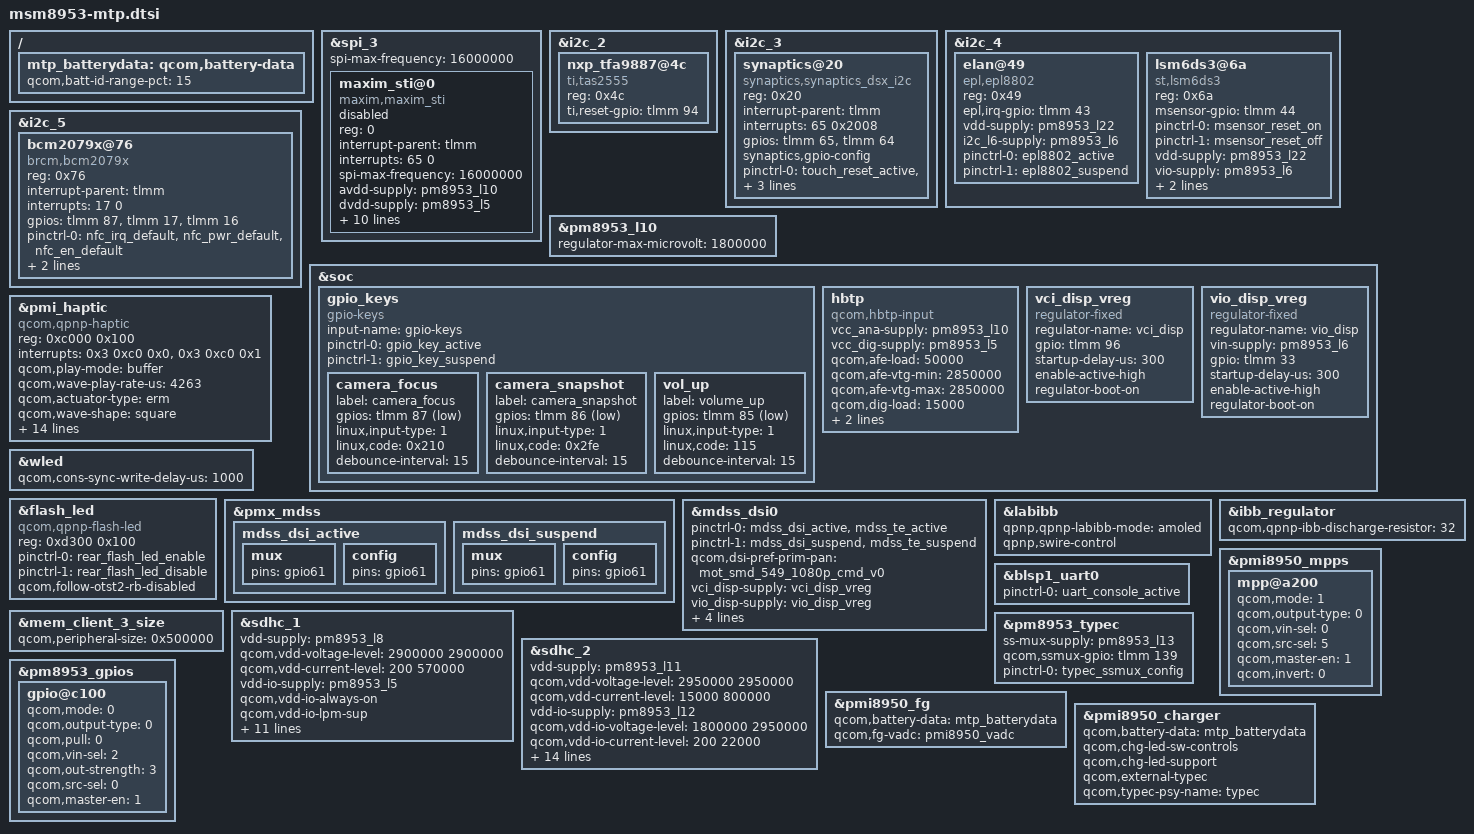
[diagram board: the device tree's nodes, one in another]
/*
 * Copyright (c) 2015-2016, The Linux Foundation. All rights reserved.
 *
 * This program is free software; you can redistribute it and/or modify
 * it under the terms of the GNU General Public License version 2 and
 * only version 2 as published by the Free Software Foundation.
 *
 * This program is distributed in the hope that it will be useful,
 * but WITHOUT ANY WARRANTY; without even the implied warranty of
 * MERCHANTABILITY or FITNESS FOR A PARTICULAR PURPOSE.  See the
 * GNU General Public License for more details.
 */
#include "msm8953-pinctrl.dtsi"
#include "msm8953-audio-mtp.dtsi"
/*lenovo-sw zhangjiano add camera dtsi 2016-03-28*/
#include "msm8953-camera-sensor-kuntao.dtsi"

&spi_3 { /* BLSP1 QUP3 */
	spi-max-frequency = <16000000>;
	maxim_sti@0 {
		status = "disabled";
		compatible = "maxim,maxim_sti";
		reg = <0>;
		interrupt-parent = <&tlmm>;
		interrupts = <65 0>;
		spi-max-frequency = <16000000>;
		avdd-supply = <&pm8953_l10>;
		dvdd-supply = <&pm8953_l5>;
		maxim_sti,irq-gpio = <&tlmm 65 0x00>;
		maxim_sti,reset-gpio = <&tlmm 64 0x00>;
		maxim_sti,touch_fusion = "/vendor/bin/touch_fusion";
		maxim_sti,config_file = "/etc/firmware/qtc800s.cfg";
		maxim_sti,fw_name = "qtc800s.bin";
		pinctrl-names = "pmx_ts_active","pmx_ts_suspend",
						"pmx_ts_release";
		pinctrl-0 = <&ts_int_active &ts_reset_active>;
		pinctrl-1 = <&ts_int_suspend &ts_reset_suspend>;
		pinctrl-2 = <&ts_release>;
	};
};
/* lenovo-sw zhangrc2 config for smartpa begin 2016-3-7 */
&i2c_2 {
    nxp_tfa9887@4c {
		compatible = "ti,tas2555";
		reg = <0x4c>;
        ti,reset-gpio = <&tlmm 94 0>;

		};
};
/* lenovo-sw zhangrc2 config for smartpa end 2016-3-7 */
&i2c_3 { /* BLSP1 QUP3 */
	synaptics@20 {
			compatible = "synaptics,synaptics_dsx_i2c";
			reg = <0x20>;
			interrupt-parent = <&tlmm>;
			interrupts = <65 0x2008>;
			gpios = <&tlmm 65 0x2008>, /* IRQ */
				<&tlmm 64 0>; /* RESET */
			synaptics,gpio-config;
			pinctrl-names = "default", "active";
			pinctrl-0 = <&touch_reset_active &touch_int_default>;
			pinctrl-1 = <&touch_reset_active &touch_int_active>;
	};
};

/*lenovo-sw caoyi1 add for sensor 20160328 begin*/
&i2c_4 {
	elan@49 {
		compatible = "epl,epl8802";
		reg = <0x49>;
		epl,irq-gpio = <&tlmm 43 0x08>;
		vdd-supply = <&pm8953_l22>;
		i2c_l6-supply = <&pm8953_l6>;
		pinctrl-names = "epl8802_default", "epl8802_suspend";
		pinctrl-0 = <&epl8802_active>;
		pinctrl-1 = <&epl8802_suspend>;
	};

	lsm6ds3@6a {
		compatible = "st,lsm6ds3";
		reg = <0x6a>;
		msensor-gpio = <&tlmm 44 0x0>;
		pinctrl-names = "msensor_reset_on", "msensor_reset_off";
		pinctrl-0 = <&msensor_reset_on>;
		pinctrl-1 = <&msensor_reset_off>;
		vdd-supply = <&pm8953_l22>;
		vio-supply = <&pm8953_l6>;
		interrupt-parent = <&tlmm>;
		interrupts = <42 0x02>;
	};
};
/*lenovo-sw caoyi1 add for sensor 20160328 begin end*/

&i2c_5 { /* BLSP2 QUP1 (NFC) */
	/*nq@28 {
		compatible = "qcom,nq-nci";
		reg = <0x28>;
		qcom,nq-irq = <&tlmm 17 0x00>;
		qcom,nq-ven = <&tlmm 16 0x00>;
		qcom,nq-firm = <&tlmm 62 0x00>;
		qcom,nq-clkreq = <&pm8953_gpios 2 0x00>;
		interrupt-parent = <&tlmm>;
		qcom,clk-src = "BBCLK2";
		interrupts = <17 0>;
		interrupt-names = "nfc_irq";
		pinctrl-names = "nfc_active", "nfc_suspend";
		pinctrl-0 = <&nfc_int_active &nfc_disable_active>;
		pinctrl-1 = <&nfc_int_suspend &nfc_disable_suspend>;
		clocks = <&clock_gcc clk_bb_clk2_pin>;
		clock-names = "ref_clk";
	};*/

	/* BCM 20797 NFC Controller */
	bcm2079x@76 {
		status = "ok";
		compatible = "brcm,bcm2079x";
		reg = <0x76>;
		interrupt-parent = <&tlmm>;
		interrupts = <17 0>; 		/* NFC_IRQ */
		gpios = <&tlmm 87 0>, 	/* NFC_ENABLE_IN */
			<&tlmm 17 0>, 		/* NFC_IRQ */
			<&tlmm 16 0>; 		/* NFC_POWER_ON */

		pinctrl-names = "default";
		pinctrl-0 = <&nfc_irq_default &nfc_pwr_default &nfc_en_default>;

		qcom,clk-gpio = <&pm8953_gpios 2 0x00>;
		clocks = <&clock_gcc clk_bb_clk2_pin>;
		clock-names = "ref_clk";
	};
};

&pm8953_l10 {
	regulator-max-microvolt = <1800000>;
};

&soc {
	gpio_keys {
		compatible = "gpio-keys";
		input-name = "gpio-keys";
		pinctrl-names = "tlmm_gpio_key_active","tlmm_gpio_key_suspend";
		pinctrl-0 = <&gpio_key_active>;
		pinctrl-1 = <&gpio_key_suspend>;

		camera_focus {
			label = "camera_focus";
			gpios = <&tlmm 87 0x1>;
			linux,input-type = <1>;
			linux,code = <0x210>;
			debounce-interval = <15>;
		};

		camera_snapshot {
			label = "camera_snapshot";
			gpios = <&tlmm 86 0x1>;
			linux,input-type = <1>;
			linux,code = <0x2fe>;
			debounce-interval = <15>;
		};


		vol_up {
			label = "volume_up";
			gpios = <&tlmm 85 0x1>;
			linux,input-type = <1>;
			linux,code = <115>;
			debounce-interval = <15>;
		};
	};

	hbtp {
		compatible = "qcom,hbtp-input";
		vcc_ana-supply = <&pm8953_l10>;
		vcc_dig-supply = <&pm8953_l5>;
		qcom,afe-load = <50000>;
		qcom,afe-vtg-min = <2850000>;
		qcom,afe-vtg-max = <2850000>;
		qcom,dig-load = <15000>;
		qcom,dig-vtg-min = <1800000>;
		qcom,dig-vtg-max = <1800000>;
	};
	vci_disp_vreg: vci_disp_vreg {
		compatible = "regulator-fixed";
		regulator-name = "vci_disp";
		gpio = <&tlmm 96 0>;
		startup-delay-us = <300>;
		enable-active-high;
		regulator-boot-on;
	};

	vio_disp_vreg: vio_disp_vreg {
		compatible = "regulator-fixed";
		regulator-name = "vio_disp";
		vin-supply = <&pm8953_l6>;
		gpio = <&tlmm 33 0>;
		startup-delay-us = <300>;
		enable-active-high;
		regulator-boot-on;
	};
};

&pmi_haptic{
	compatible = "qcom,qpnp-haptic";
	reg = <0xc000 0x100>;
	interrupts = <0x3 0xc0 0x0>,
			<0x3 0xc0 0x1>;
	interrupt-names = "sc-irq", "play-irq";
	qcom,play-mode = "buffer";
	qcom,wave-play-rate-us = <4263>;
	qcom,actuator-type = "erm";
	qcom,wave-shape = "square";
	qcom,vmax-mv = <3200>;
	qcom,ilim-ma = <100>;
	qcom,sc-deb-cycles = <8>;
	qcom,int-pwm-freq-khz = <505>;
	qcom,en-brake;
	qcom,context-haptics;
	qcom,brake-pattern = [03 02 00 00];
	qcom,use-play-irq;
	qcom,use-sc-irq;
	qcom,wave-samples = [5c 5c 5c 5c 5c 5c 5c 5c];
	qcom,wave-samples_low = [54 54 54 54 54 54 54 54];
	qcom,wave-rep-cnt = <1>;
	qcom,wave-samp-rep-cnt = <1>;
};


&wled {
	qcom,cons-sync-write-delay-us = <1000>;
};
/*lenovo-sw zhangjiano add camera dtsi 2016-03-28*/
&flash_led {
	compatible = "qcom,qpnp-flash-led";
	reg = <0xd300 0x100>;
	pinctrl-names = "flash_led_enable","flash_led_disable";
	pinctrl-0 = <&rear_flash_led_enable>;
	pinctrl-1 = <&rear_flash_led_disable>;
	qcom,follow-otst2-rb-disabled;
};

#include "dsi-panel-mot-smd-549-1080p-cmd.dtsi"
#include "dsi-panel-mot-dummy-qhd-video.dtsi"
//#include "msm8953-mdss-panels.dtsi"

&pmx_mdss {
	mdss_dsi_active {
		mux {
			pins = "gpio61";
		};

		config {
			pins = "gpio61";
		};
	};

	mdss_dsi_suspend {
		mux {
			pins = "gpio61";
		};

		config {
			pins = "gpio61";
		};
	};
};

&mdss_dsi0 {
	pinctrl-names = "mdss_default", "mdss_sleep";
	pinctrl-0 = <&mdss_dsi_active &mdss_te_active>;
	pinctrl-1 = <&mdss_dsi_suspend &mdss_te_suspend>;

	qcom,dsi-pref-prim-pan = <&mot_smd_549_1080p_cmd_v0>;
	vci_disp-supply = <&vci_disp_vreg>;
	vio_disp-supply = <&vio_disp_vreg>;
	elvdd_disp-supply = <&lab_regulator>;
	elvss_disp-supply = <&ibb_regulator>;
	qcom,platform-reset-gpio = <&tlmm 61 0>;
	qcom,platform-te-gpio = <&tlmm 24 0>;
};

/* display boost and inverting boost regulators */
&labibb {
	status = "ok";
	qpnp,qpnp-labibb-mode = "amoled";
	qpnp,swire-control;
};

&ibb_regulator {
	qcom,qpnp-ibb-discharge-resistor = <32>;
};

&pmi8950_mpps {
	mpp@a200 {
		qcom,mode = <1>;		/* Digital output */
		qcom,output-type = <0>;		/* CMOS logic */
		qcom,vin-sel = <0>;
		qcom,src-sel = <5>;		/* DTEST2 */
		qcom,master-en = <1>;		/* Enable GPIO */
		qcom,invert = <0>;
		status = "okay";
	};
};

&blsp1_uart0 {
	status = "ok";
	pinctrl-names = "default";
	pinctrl-0 = <&uart_console_active>;
};

&mem_client_3_size {
	qcom,peripheral-size = <0x500000>;
};

&sdhc_1 {
	/* device core power supply */
	vdd-supply = <&pm8953_l8>;
	qcom,vdd-voltage-level = <2900000 2900000>;
	qcom,vdd-current-level = <200 570000>;

	/* device communication power supply */
	vdd-io-supply = <&pm8953_l5>;
	qcom,vdd-io-always-on;
	qcom,vdd-io-lpm-sup;
	qcom,vdd-io-voltage-level = <1800000 1800000>;
	qcom,vdd-io-current-level = <200 325000>;

	pinctrl-names = "active", "sleep";
	pinctrl-0 = <&sdc1_clk_on &sdc1_cmd_on &sdc1_data_on  &sdc1_rclk_on>;
	pinctrl-1 = <&sdc1_clk_off &sdc1_cmd_off &sdc1_data_off &sdc1_rclk_off>;

	qcom,clk-rates = <400000 20000000 25000000 50000000 100000000 192000000
								384000000>;
	qcom,nonremovable;
	qcom,bus-speed-mode = "HS400_1p8v", "HS200_1p8v", "DDR_1p8v";

	status = "ok";
};

&sdhc_2 {
	/* device core power supply */
	vdd-supply = <&pm8953_l11>;
	qcom,vdd-voltage-level = <2950000 2950000>;
	qcom,vdd-current-level = <15000 800000>;

	/* device communication power supply */
	vdd-io-supply = <&pm8953_l12>;
	qcom,vdd-io-voltage-level = <1800000 2950000>;
	qcom,vdd-io-current-level = <200 22000>;

	pinctrl-names = "active", "sleep";
	pinctrl-0 = <&sdc2_clk_on &sdc2_cmd_on &sdc2_data_on &sdc2_cd_on>;
	pinctrl-1 = <&sdc2_clk_off &sdc2_cmd_off &sdc2_data_off>;

	#address-cells = <0>;
	interrupt-parent = <&sdhc_2>;
	interrupts = <0 1 2>;
	#interrupt-cells = <1>;
	interrupt-map-mask = <0xffffffff>;
	interrupt-map = <0 &intc 0 125 0
		1 &intc 0 221 0
		2 &tlmm 133 0>;
	interrupt-names = "hc_irq", "pwr_irq", "status_irq";
	cd-gpios = <&tlmm 133 0x0>;

	qcom,clk-rates = <400000 20000000 25000000 50000000 100000000
								200000000>;
	qcom,bus-speed-mode = "SDR12", "SDR25", "SDR50", "DDR50", "SDR104";

	status = "ok";
};

&pm8953_typec {
	ss-mux-supply = <&pm8953_l13>;
	qcom,ssmux-gpio = <&tlmm 139 GPIO_ACTIVE_HIGH>;
	pinctrl-names = "default";
	pinctrl-0 = <&typec_ssmux_config>;
};

/{
	mtp_batterydata: qcom,battery-data {
		qcom,batt-id-range-pct = <15>;
		#include "batterydata-kuntao-5000mah.dtsi"
		#include "batterydata-kuntao-2-5000mah.dtsi"
	};
};

&pmi8950_fg {
	qcom,battery-data = <&mtp_batterydata>;
	qcom,fg-vadc = <&pmi8950_vadc>;
};
/*
&usb3 {
	vbus_dwc3-supply = <&bq2589x_otg_supply>;
};
*/
&pmi8950_charger {
	qcom,battery-data = <&mtp_batterydata>;
	qcom,chg-led-sw-controls;
	qcom,chg-led-support;
	qcom,external-typec;
	qcom,typec-psy-name = "typec";
};

&pm8953_gpios {
	/* GPIO 2 (NFC_CLK_REQ) */
	gpio@c100 {
		qcom,mode = <0>;
		qcom,output-type = <0>;
		qcom,pull = <0>;
		qcom,vin-sel = <2>;
		qcom,out-strength = <3>;
		qcom,src-sel = <0>;
		qcom,master-en = <1>;
		status = "okay";
	};
};
